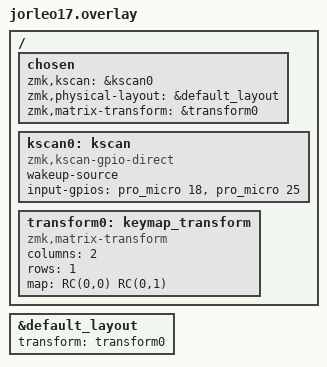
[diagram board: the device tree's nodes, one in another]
// This file was generated from a template. Edit it to match your keyboard.
// See https://zmk.dev/docs/development/hardware-integration/new-shield for more
// instructions.
#include <dt-bindings/zmk/matrix_transform.h>
#include "jorleo17-layouts.dtsi"

&default_layout {
    transform = <&transform0>;
};

/ {
    
    chosen {
        zmk,kscan = &kscan0;
        zmk,physical-layout = &default_layout;
        zmk,matrix-transform = &transform0;
        };

    kscan0: kscan {

        compatible = "zmk,kscan-gpio-direct";
        wakeup-source;

        input-gpios
            = <&pro_micro 18 (GPIO_ACTIVE_HIGH | GPIO_PULL_DOWN)>
            , <&pro_micro 25 (GPIO_ACTIVE_HIGH | GPIO_PULL_DOWN)>
            ;
    };
    transform0: keymap_transform {
        compatible = "zmk,matrix-transform";
        columns = <2>;
        rows = <1>;
        map = <
        RC(0,0)  RC(0,1)
        >;
    };
};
